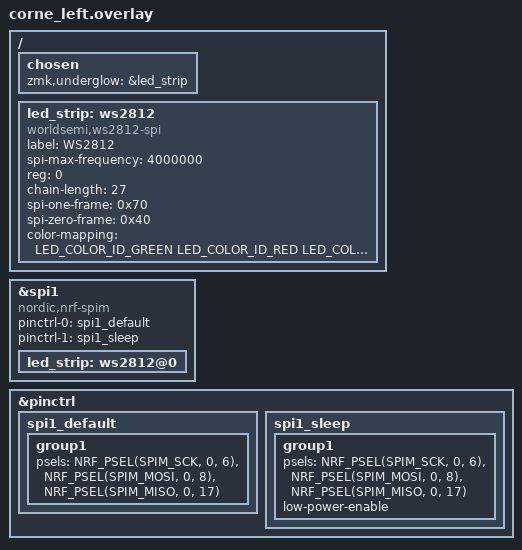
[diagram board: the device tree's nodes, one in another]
/ {
    chosen {
        zmk,underglow = &led_strip;
    };

    led_strip: ws2812 {
        compatible = "worldsemi,ws2812-spi";
        label = "WS2812";

        /* SPI */
        spi-max-frequency = <4000000>;
        reg = <0>; /* ignored, but necessary for SPI bindings */
        chain-length = <27>; /* number of LEDs */
        spi-one-frame = <0x70>;
        spi-zero-frame = <0x40>;
        
        color-mapping = <LED_COLOR_ID_GREEN LED_COLOR_ID_RED LED_COLOR_ID_BLUE>;
    };
};

&spi1 {
    status = "okay";
    compatible = "nordic,nrf-spim";
    pinctrl-0 = <&spi1_default>;
    pinctrl-1 = <&spi1_sleep>;
    pinctrl-names = "default", "sleep";

    led_strip: ws2812@0 {
        status = "okay";
    };
};

&pinctrl {
    spi1_default: spi1_default {
        group1 {
            psels = <NRF_PSEL(SPIM_SCK, 0, 6)>,
                <NRF_PSEL(SPIM_MOSI, 0, 8)>,
                <NRF_PSEL(SPIM_MISO, 0, 17)>;
        };
    };

    spi1_sleep: spi1_sleep {
        group1 {
            psels = <NRF_PSEL(SPIM_SCK, 0, 6)>,
                <NRF_PSEL(SPIM_MOSI, 0, 8)>,
                <NRF_PSEL(SPIM_MISO, 0, 17)>;
            low-power-enable;
        };
    };
};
